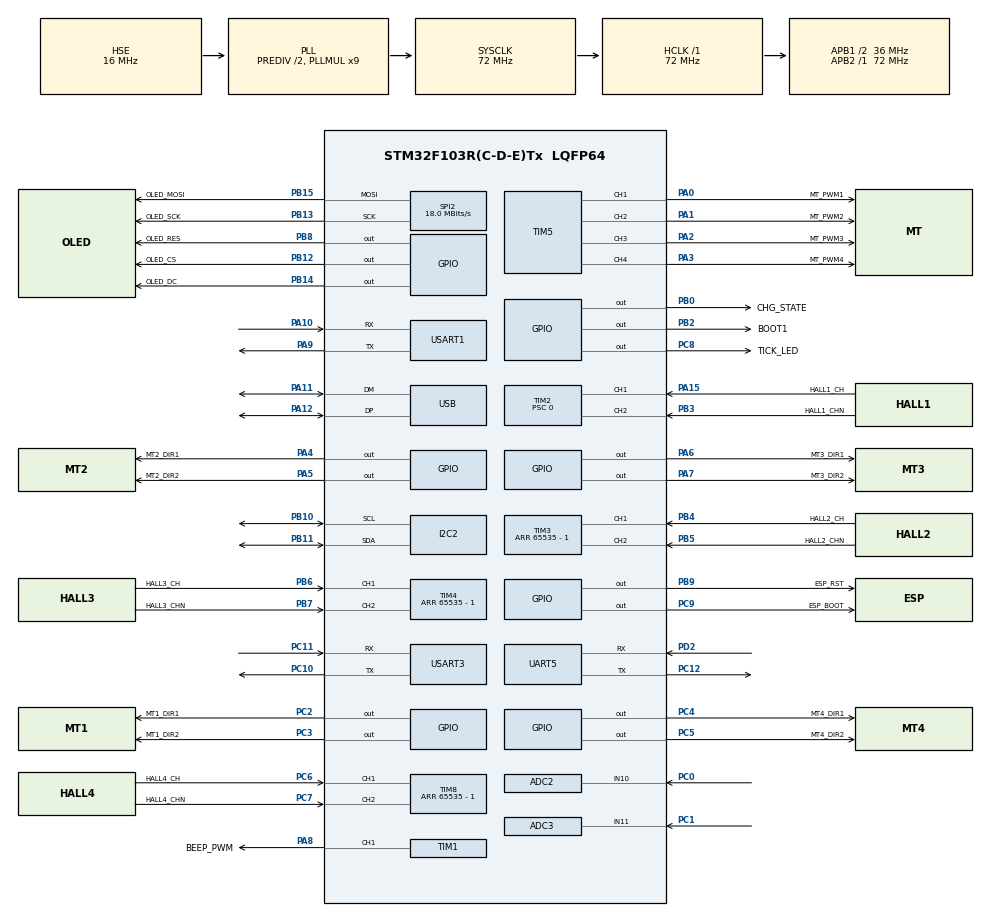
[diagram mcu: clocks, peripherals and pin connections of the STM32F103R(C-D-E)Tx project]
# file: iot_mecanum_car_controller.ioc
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ADC2.Channel-0\#ChannelRegularConversion=ADC_CHANNEL_10
ADC2.NbrOfConversionFlag=1
ADC2.Rank-0\#ChannelRegularConversion=1
ADC2.SamplingTime-0\#ChannelRegularConversion=ADC_SAMPLETIME_1CYCLE_5
ADC3.Channel-1\#ChannelRegularConversion=ADC_CHANNEL_11
ADC3.EnableRegularConversion=ENABLE
ADC3.NbrOfConversion=1
ADC3.NbrOfConversionFlag=1
ADC3.Rank-1\#ChannelRegularConversion=1
ADC3.SamplingTime-1\#ChannelRegularConversion=ADC_SAMPLETIME_1CYCLE_5
Dma.Request0=SPI2_TX
Dma.Request1=USART1_TX
Dma.Request2=USART3_TX
Dma.SPI2_TX.0.Direction=DMA_MEMORY_TO_PERIPH
Dma.SPI2_TX.0.Instance=DMA1_Channel5
Dma.SPI2_TX.0.MemDataAlignment=DMA_MDATAALIGN_BYTE
Dma.SPI2_TX.0.MemInc=DMA_MINC_ENABLE
Dma.SPI2_TX.0.Mode=DMA_CIRCULAR
Dma.SPI2_TX.0.PeriphDataAlignment=DMA_PDATAALIGN_BYTE
Dma.SPI2_TX.0.PeriphInc=DMA_PINC_DISABLE
Dma.SPI2_TX.0.Priority=DMA_PRIORITY_MEDIUM
Dma.USART1_TX.1.Direction=DMA_MEMORY_TO_PERIPH
Dma.USART1_TX.1.Instance=DMA1_Channel4
Dma.USART1_TX.1.MemDataAlignment=DMA_MDATAALIGN_BYTE
Dma.USART1_TX.1.MemInc=DMA_MINC_ENABLE
Dma.USART1_TX.1.Mode=DMA_NORMAL
Dma.USART1_TX.1.PeriphDataAlignment=DMA_PDATAALIGN_BYTE
Dma.USART1_TX.1.PeriphInc=DMA_PINC_DISABLE
Dma.USART1_TX.1.Priority=DMA_PRIORITY_LOW
Dma.USART3_TX.2.Direction=DMA_MEMORY_TO_PERIPH
Dma.USART3_TX.2.Instance=DMA1_Channel2
Dma.USART3_TX.2.MemDataAlignment=DMA_MDATAALIGN_BYTE
Dma.USART3_TX.2.MemInc=DMA_MINC_ENABLE
Dma.USART3_TX.2.Mode=DMA_NORMAL
Dma.USART3_TX.2.PeriphDataAlignment=DMA_PDATAALIGN_BYTE
Dma.USART3_TX.2.PeriphInc=DMA_PINC_DISABLE
Dma.USART3_TX.2.Priority=DMA_PRIORITY_LOW
Mcu.Family=STM32F1
Mcu.Name=STM32F103R(C-D-E)Tx
Mcu.Package=LQFP64
Mcu.UserConstants=OLED_SPI,$$_SPI2_IP_HANDLE_$$;PWM_TIM,$$_TIM5_IP_HANDLE_$$;BEEP_TIM,$$_TIM1_IP_HANDLE_$$;HALL1_TIM,$$_TIM2_IP_HANDLE_$$;HALL2_TIM,$$_TIM3_IP_HANDLE_$$;HALL3_TIM,$$_TIM4_IP_HANDLE_$$;HALL4_TIM,$$_TIM8_IP_HANDLE_$$
NVIC.ADC1_2_IRQn=true\:14\:0\:true\:false\:true\:true\:true\:true
NVIC.ADC3_IRQn=true\:0\:0\:true\:false\:true\:true\:true\:true
NVIC.DMA1_Channel2_IRQn=true\:0\:0\:false\:false\:true\:false\:true\:true
NVIC.DMA1_Channel4_IRQn=true\:0\:0\:false\:false\:true\:false\:true\:true
NVIC.DMA1_Channel5_IRQn=true\:0\:0\:false\:false\:true\:false\:true\:true
NVIC.PriorityGroup=NVIC_PRIORITYGROUP_4
NVIC.TIM6_IRQn=true\:14\:0\:true\:false\:true\:true\:true\:true
NVIC.TIM7_IRQn=true\:15\:0\:false\:false\:true\:false\:true\:true
NVIC.TimeBase=TIM7_IRQn
NVIC.TimeBaseIP=TIM7
NVIC.UART5_IRQn=true\:0\:0\:false\:false\:true\:true\:true\:true
NVIC.USART1_IRQn=true\:0\:0\:true\:false\:true\:true\:true\:true
NVIC.USART3_IRQn=true\:0\:0\:false\:false\:true\:true\:true\:true
NVIC.USB_LP_CAN1_RX0_IRQn=true\:0\:0\:false\:false\:true\:false\:true\:true
PA0-WKUP.GPIO_Label=MT_PWM1
PA0-WKUP.Signal=S_TIM5_CH1
PA1.GPIO_Label=MT_PWM2
PA1.Signal=S_TIM5_CH2
PA10.Mode=Asynchronous
PA10.Signal=USART1_RX
PA11.Mode=Device
PA11.Signal=USB_DM
PA12.Mode=Device
PA12.Signal=USB_DP
PA13.Mode=Serial_Wire
PA13.Signal=SYS_JTMS-SWDIO
PA14.Mode=Serial_Wire
PA14.Signal=SYS_JTCK-SWCLK
PA15.GPIO_Label=HALL1_CH
PA15.Signal=S_TIM2_CH1_ETR
PA2.GPIO_Label=MT_PWM3
PA2.Signal=S_TIM5_CH3
PA3.GPIO_Label=MT_PWM4
PA3.Signal=S_TIM5_CH4
PA4.GPIO_Label=MT2_DIR1
PA4.Signal=GPIO_Output
PA5.GPIO_Label=MT2_DIR2
PA5.Signal=GPIO_Output
PA6.GPIO_Label=MT3_DIR1
PA6.Signal=GPIO_Output
PA7.GPIO_Label=MT3_DIR2
PA7.Signal=GPIO_Output
PA8.GPIO_Label=BEEP_PWM
PA8.Signal=S_TIM1_CH1
PA9.Mode=Asynchronous
PA9.Signal=USART1_TX
PB0.GPIO_Label=CHG_STATE
PB0.Signal=GPIO_Output
PB10.Mode=I2C
PB10.Signal=I2C2_SCL
PB11.Mode=I2C
PB11.Signal=I2C2_SDA
PB12.GPIO_Label=OLED_CS
PB12.Signal=GPIO_Output
PB13.GPIO_Label=OLED_SCK
PB13.Mode=TX_Only_Simplex_Unidirect_Master
PB13.Signal=SPI2_SCK
PB14.GPIO_Label=OLED_DC
PB14.Signal=GPIO_Output
PB15.GPIO_Label=OLED_MOSI
PB15.Mode=TX_Only_Simplex_Unidirect_Master
PB15.Signal=SPI2_MOSI
PB2.GPIO_Label=BOOT1
PB2.Signal=GPIO_Output
PB3.GPIO_Label=HALL1_CHN
PB3.Signal=S_TIM2_CH2
PB4.GPIO_Label=HALL2_CH
PB4.Signal=S_TIM3_CH1
PB5.GPIO_Label=HALL2_CHN
PB5.Signal=S_TIM3_CH2
PB6.GPIO_Label=HALL3_CH
PB6.Signal=S_TIM4_CH1
PB7.GPIO_Label=HALL3_CHN
PB7.Signal=S_TIM4_CH2
PB8.GPIO_Label=OLED_RES
PB8.Signal=GPIO_Output
PB9.GPIO_Label=ESP_RST
PB9.Signal=GPIO_Output
PC0.Signal=ADCx_IN10
PC1.Signal=ADCx_IN11
PC10.Mode=Asynchronous
PC10.Signal=USART3_TX
PC11.Mode=Asynchronous
PC11.Signal=USART3_RX
PC12.Mode=Asynchronous
PC12.Signal=UART5_TX
PC14-OSC32_IN.Mode=LSE-External-Oscillator
PC14-OSC32_IN.Signal=RCC_OSC32_IN
PC15-OSC32_OUT.Mode=LSE-External-Oscillator
PC15-OSC32_OUT.Signal=RCC_OSC32_OUT
PC2.GPIO_Label=MT1_DIR1
PC2.Signal=GPIO_Output
PC3.GPIO_Label=MT1_DIR2
PC3.Signal=GPIO_Output
PC4.GPIO_Label=MT4_DIR1
PC4.Signal=GPIO_Output
PC5.GPIO_Label=MT4_DIR2
PC5.Signal=GPIO_Output
PC6.GPIO_Label=HALL4_CH
PC6.Signal=S_TIM8_CH1
PC7.GPIO_Label=HALL4_CHN
PC7.Signal=S_TIM8_CH2
PC8.GPIO_Label=TICK_LED
PC8.Signal=GPIO_Output
PC9.GPIO_Label=ESP_BOOT
PC9.Signal=GPIO_Output
PD0-OSC_IN.Mode=HSE-External-Oscillator
PD0-OSC_IN.Signal=RCC_OSC_IN
PD1-OSC_OUT.Mode=HSE-External-Oscillator
PD1-OSC_OUT.Signal=RCC_OSC_OUT
PD2.Mode=Asynchronous
PD2.Signal=UART5_RX
ProjectManager.HeapSize=0x800
ProjectManager.StackSize=0x400
ProjectManager.TargetToolchain=MDK-ARM V5.32
RCC.ADCPresc=RCC_ADCPCLK2_DIV6
RCC.AHBFreq_Value=72000000
RCC.APB1CLKDivider=RCC_HCLK_DIV2
RCC.APB1Freq_Value=36000000
RCC.APB1TimFreq_Value=72000000
RCC.APB2Freq_Value=72000000
RCC.APB2TimFreq_Value=72000000
RCC.HCLKFreq_Value=72000000
RCC.HSEDivPLL=RCC_HSE_PREDIV_DIV2
RCC.HSE_VALUE=16000000
RCC.PLLMUL=RCC_PLL_MUL9
RCC.PLLSourceVirtual=RCC_PLLSOURCE_HSE
RCC.SYSCLKFreq_VALUE=72000000
RCC.SYSCLKSource=RCC_SYSCLKSOURCE_PLLCLK
RCC.USBFreq_Value=48000000
RCC.USBPrescaler=RCC_USBCLKSOURCE_PLL_DIV1_5
SH.ADCx_IN10.0=ADC2_IN10,IN10
SH.ADCx_IN11.0=ADC3_IN11,IN11
SH.S_TIM1_CH1.0=TIM1_CH1,PWM Generation1 CH1
SH.S_TIM2_CH1_ETR.0=TIM2_CH1,Encoder_Interface
SH.S_TIM2_CH2.0=TIM2_CH2,Encoder_Interface
SH.S_TIM3_CH1.0=TIM3_CH1,Encoder_Interface
SH.S_TIM3_CH2.0=TIM3_CH2,Encoder_Interface
SH.S_TIM4_CH1.0=TIM4_CH1,Encoder_Interface
SH.S_TIM4_CH2.0=TIM4_CH2,Encoder_Interface
SH.S_TIM5_CH1.0=TIM5_CH1,PWM Generation1 CH1
SH.S_TIM5_CH2.0=TIM5_CH2,PWM Generation2 CH2
SH.S_TIM5_CH3.0=TIM5_CH3,PWM Generation3 CH3
SH.S_TIM5_CH4.0=TIM5_CH4,PWM Generation4 CH4
SH.S_TIM8_CH1.0=TIM8_CH1,Encoder_Interface
SH.S_TIM8_CH2.0=TIM8_CH2,Encoder_Interface
SPI2.CalculateBaudRate=18.0 MBits/s
SPI2.Direction=SPI_DIRECTION_2LINES
SPI2.Mode=SPI_MODE_MASTER
SPI2.VirtualType=VM_MASTER
TIM1.AutoReloadPreload=TIM_AUTORELOAD_PRELOAD_ENABLE
TIM1.Channel-PWM\ Generation1\ CH1=TIM_CHANNEL_1
TIM1.Period=36000 - 1
TIM1.Prescaler=0
TIM1.Pulse-PWM\ Generation1\ CH1=18000
TIM2.EncoderMode=TIM_ENCODERMODE_TI1
TIM2.Period=65535 - 1
TIM2.Prescaler=0
TIM3.EncoderMode=TIM_ENCODERMODE_TI2
TIM3.Period=65535 - 1
TIM4.EncoderMode=TIM_ENCODERMODE_TI1
TIM4.Period=65535 - 1
TIM5.Channel-PWM\ Generation1\ CH1=TIM_CHANNEL_1
TIM5.Channel-PWM\ Generation2\ CH2=TIM_CHANNEL_2
TIM5.Channel-PWM\ Generation3\ CH3=TIM_CHANNEL_3
TIM5.Channel-PWM\ Generation4\ CH4=TIM_CHANNEL_4
TIM6.AutoReloadPreload=TIM_AUTORELOAD_PRELOAD_ENABLE
TIM6.Period=5000
TIM6.Prescaler=72 - 1
TIM8.EncoderMode=TIM_ENCODERMODE_TI1
TIM8.Period=65535 - 1
UART5.VirtualMode=Asynchronous
USART1.VirtualMode=VM_ASYNC
USART3.VirtualMode=VM_ASYNC
USB_DEVICE.APP_RX_DATA_SIZE=512
USB_DEVICE.APP_TX_DATA_SIZE=512
USB_DEVICE.CLASS_NAME_FS=CDC
USB_DEVICE.PRODUCT_STRING_CDC_FS=STM32 Virtual ComPort
USB_DEVICE.VirtualMode=Cdc
USB_DEVICE.VirtualModeFS=Cdc_FS
VP_SYS_VS_tim7.Mode=TIM7
VP_TIM1_VS_ClockSourceINT.Mode=Internal
VP_TIM5_VS_ClockSourceINT.Mode=Internal
VP_TIM6_VS_ClockSourceINT.Mode=Enable_Timer
VP_USB_DEVICE_VS_USB_DEVICE_CDC_FS.Mode=CDC_FS
board=custom

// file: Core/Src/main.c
/* USER CODE BEGIN Header */
/**
  ******************************************************************************
  * @file           : main.c
  * @brief          : Main program body
  ******************************************************************************
  * @attention
  *
  * Copyright (c) 2022 STMicroelectronics.
  * All rights reserved.
  *
  * This software is licensed under terms that can be found in the LICENSE file
  * in the root directory of this software component.
  * If no LICENSE file comes with this software, it is provided AS-IS.
  *
  ******************************************************************************
  */
/* USER CODE END Header */
#include "main.h"
#include "adc.h"
#include "dma.h"
#include "i2c.h"
#include "spi.h"
#include "tim.h"
#include "usart.h"
#include "usb_device.h"
#include "gpio.h"

void SystemClock_Config(void);

int main(void)
{

  /* MCU Configuration--------------------------------------------------------*/

  /* Reset of all peripherals, Initializes the Flash interface and the Systick. */
  HAL_Init();

  /* Configure the system clock */
  SystemClock_Config();

  /* Initialize all configured peripherals */
  MX_GPIO_Init();
  MX_DMA_Init();
  MX_ADC3_Init();
  MX_I2C2_Init();
  MX_SPI2_Init();
  MX_TIM1_Init();
  MX_TIM2_Init();
  MX_TIM3_Init();
  MX_TIM4_Init();
  MX_TIM5_Init();
  MX_TIM8_Init();
  MX_UART5_Init();
  MX_USART1_UART_Init();
  MX_USART3_UART_Init();
  MX_USB_DEVICE_Init();
  MX_TIM6_Init();
  MX_ADC2_Init();

  /* Infinite loop */
  /* USER CODE BEGIN WHILE */
	extern void user_main(void);
	user_main();
  while (1)
  {
    /* USER CODE END WHILE */

  }
}

void SystemClock_Config(void)
{
  RCC_OscInitTypeDef RCC_OscInitStruct = {0};
  RCC_ClkInitTypeDef RCC_ClkInitStruct = {0};
  RCC_PeriphCLKInitTypeDef PeriphClkInit = {0};

  /** Initializes the RCC Oscillators according to the specified parameters
  * in the RCC_OscInitTypeDef structure.
  */
  RCC_OscInitStruct.OscillatorType = RCC_OSCILLATORTYPE_HSE;
  RCC_OscInitStruct.HSEState = RCC_HSE_ON;
  RCC_OscInitStruct.HSEPredivValue = RCC_HSE_PREDIV_DIV2;
  RCC_OscInitStruct.HSIState = RCC_HSI_ON;
  RCC_OscInitStruct.PLL.PLLState = RCC_PLL_ON;
  RCC_OscInitStruct.PLL.PLLSource = RCC_PLLSOURCE_HSE;
  RCC_OscInitStruct.PLL.PLLMUL = RCC_PLL_MUL9;
  if (HAL_RCC_OscConfig(&RCC_OscInitStruct) != HAL_OK)
  {
    Error_Handler();
  }

  /** Initializes the CPU, AHB and APB buses clocks
  */
  RCC_ClkInitStruct.ClockType = RCC_CLOCKTYPE_HCLK|RCC_CLOCKTYPE_SYSCLK
                              |RCC_CLOCKTYPE_PCLK1|RCC_CLOCKTYPE_PCLK2;
  RCC_ClkInitStruct.SYSCLKSource = RCC_SYSCLKSOURCE_PLLCLK;
  RCC_ClkInitStruct.AHBCLKDivider = RCC_SYSCLK_DIV1;
  RCC_ClkInitStruct.APB1CLKDivider = RCC_HCLK_DIV2;
  RCC_ClkInitStruct.APB2CLKDivider = RCC_HCLK_DIV1;

  if (HAL_RCC_ClockConfig(&RCC_ClkInitStruct, FLASH_LATENCY_2) != HAL_OK)
  {
    Error_Handler();
  }
  PeriphClkInit.PeriphClockSelection = RCC_PERIPHCLK_ADC|RCC_PERIPHCLK_USB;
  PeriphClkInit.AdcClockSelection = RCC_ADCPCLK2_DIV6;
  PeriphClkInit.UsbClockSelection = RCC_USBCLKSOURCE_PLL_DIV1_5;
  if (HAL_RCCEx_PeriphCLKConfig(&PeriphClkInit) != HAL_OK)
  {
    Error_Handler();
  }
}

void HAL_TIM_PeriodElapsedCallback(TIM_HandleTypeDef *htim)
{
  if (htim->Instance == TIM7) {
    HAL_IncTick();
  }
}

void Error_Handler(void)
{
  __disable_irq();
  while (1)
  {
  }
}
